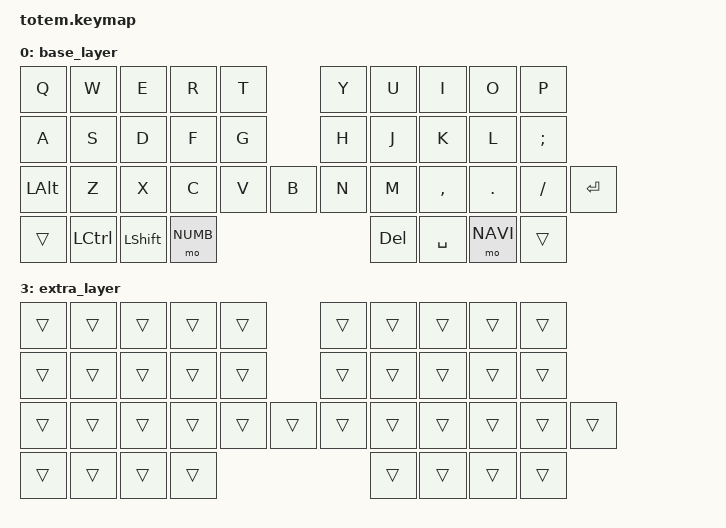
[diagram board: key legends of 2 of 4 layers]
#include <behaviors.dtsi>
#include <dt-bindings/zmk/keys.h>
#include <dt-bindings/zmk/bt.h>
#include <dt-bindings/zmk/outputs.h>

/* Helper: 이 레포의 ZMK_LAYER / 키 포지션 매크로를 사용 */
#include "./totem_key_position.h"
#include "./totem_macro.h"

/* ===================== */
/* Layer index (스샷 기준) */
/* ===================== */
#define BASE  0
#define NUMB  1   /* mo(1) */
#define NAVI  2   /* mo(2) */
#define EXTRA 3   /* 스샷의 mo(3) 자리 때문에 비워둠 */

/* Alias */
#define __________ &trans

/* ===================== */
/* Keymap                */
/* ===================== */

/*
스샷 기준 물리 배치 해석:
- 3번째 줄(하단 row)에 좌/우 "추가 1키"가 있음:
  - 왼쪽 추가키 = ALT
  - 오른쪽 추가키 = Enter
- 엄지 row(각 3키):
  - 왼쪽: ctrl / shift / mo(1)=NUMB
  - 오른쪽: del / space / mo(2)=NAVI
*/

/* --------------------- */
/* BASE                  */
/* --------------------- */
ZMK_LAYER(base_layer, /*
╭────────────┬────────────┬────────────┬────────────┬────────────╮╭────────────┬────────────┬────────────┬────────────┬────────────╮
*/&kp Q        &kp W        &kp E        &kp R        &kp T         &kp Y        &kp U        &kp I        &kp O        &kp P     /*
├────────────┼────────────┼────────────┼────────────┼────────────┤├────────────┼────────────┼────────────┼────────────┼────────────┤
*/&kp A        &kp S        &kp D        &kp F        &kp G         &kp H        &kp J        &kp K        &kp L        &kp SEMI  /*
├────────────┼────────────┼────────────┼────────────┼────────────┤├────────────┼────────────┼────────────┼────────────┼────────────┤
*/&kp LALT     &kp Z        &kp X        &kp C        &kp V  &kp B   &kp N        &kp M        &kp COMMA    &kp DOT      &kp FSLH   &kp ENTER/*
╰────────────┴────────────┴────────────┴────────────┴────────────╯╰────────────┴────────────┴────────────┴────────────┴────────────╯
╭────────────╮            ╭────────────┬────────────┬────────────╮╭────────────┬────────────┬────────────╮            ╭────────────╮
*/__________                &kp LCTRL     &kp LSHIFT   &mo NUMB      &kp DEL      &kp SPACE    &mo NAVI                __________/*
╰────────────╯            ╰────────────┴────────────┴────────────╯╰────────────┴────────────┴────────────╯            ╰────────────╯
*/)

/* --------------------- */
/* NUMB (mo(1))          */
/* --------------------- */
ZMK_LAYER(numb_layer, /*
╭────────────┬────────────┬────────────┬────────────┬────────────╮╭────────────┬────────────┬────────────┬────────────┬────────────╮
*/&kp N1       &kp N2       &kp N3       &kp N4       &kp N5        &kp N6       &kp N7       &kp N8       &kp N9       &kp N0     /*
├────────────┼────────────┼────────────┼────────────┼────────────┤├────────────┼────────────┼────────────┼────────────┼────────────┤
*/&kp EXCL     &kp AT       &kp HASH     &kp DLLR     &kp PRCNT     &kp CARET    &kp AMPS     &kp STAR     &kp LPAR     &kp RPAR   /*
├────────────┼────────────┼────────────┼────────────┼────────────┤├────────────┼────────────┼────────────┼────────────┼────────────┤
*/&kp ESC      &kp LC(A)    &kp LC(X)    &kp LC(C)    &kp LC(V) &kp LC(ENTER)   &kp MINUS    &kp LBKT     &kp RBKT     __________   &kp LA(TAB)/*
╰────────────┴────────────┴────────────┴────────────┴────────────╯╰────────────┴────────────┴────────────┴────────────┴────────────╯
╭────────────╮            ╭────────────┬────────────┬────────────╮╭────────────┬────────────┬────────────╮            ╭────────────╮
*/__________                &kp LANG1     &mo NAVI     &trans      &kp EQUAL    &kp LSHIFT   &mo EXTRA               __________/*
╰────────────╯            ╰────────────┴────────────┴────────────╯╰────────────┴────────────┴────────────╯            ╰────────────╯
*/)

/*
- 스샷의 -/_ 는 MINUS(Shift 시 _)
- 스샷의 +/= 는 EQUAL(Shift 시 +)
- 스샷의 [/{ 와 ]/} 는 LBKT/RBKT(Shift 시 { })
- alt+tab은 LA(TAB)
- LCTRL+ENTER는 LC(ENTER)
- mo(3)은 EXTRA 레이어로 두되, 아직 비워둠
*/

/* --------------------- */
/* NAVI (mo(2))          */
/* --------------------- */
ZMK_LAYER(navi_layer, /*
╭────────────┬────────────┬────────────┬────────────┬────────────╮╭────────────┬────────────┬────────────┬────────────┬────────────╮
*/&kp F1       &kp F2       &kp F3       &kp F4       &kp F5        &kp F6       &kp F7       &kp F8       &kp F9       &kp F10    /*
├────────────┼────────────┼────────────┼────────────┼────────────┤├────────────┼────────────┼────────────┼────────────┼────────────┤
*/&kp HOME     __________    __________    &kp F11      &kp F12       __________   &kp UP       __________   &kp PG_UP    &kp C_VOL_UP/*
├────────────┼────────────┼────────────┼────────────┼────────────┤├────────────┼────────────┼────────────┼────────────┼────────────┤
*/&kp END      __________    __________    __________    __________    &kp LEFT     &kp DOWN     &kp RIGHT    &kp PG_DN    &kp C_VOL_DN &kp LA(TAB)/*
╰────────────┴────────────┴────────────┴────────────┴────────────╯╰────────────┴────────────┴────────────┴────────────┴────────────╯
╭────────────╮            ╭────────────┬────────────┬────────────╮╭────────────┬────────────┬────────────╮            ╭────────────╮
*/__________                __________    __________    __________    __________   __________    __________              __________/*
╰────────────╯            ╰────────────┴────────────┴────────────╯╰────────────┴────────────┴────────────╯            ╰────────────╯
*/)

/* --------------------- */
/* EXTRA (mo(3))         */
/* - 아직 미지정: 전부 투과 */
/* --------------------- */
ZMK_LAYER(extra_layer, /*
╭────────────┬────────────┬────────────┬────────────┬────────────╮╭────────────┬────────────┬────────────┬────────────┬────────────╮
*/__________   __________   __________   __________   __________    __________   __________   __________   __________   __________/*
├────────────┼────────────┼────────────┼────────────┼────────────┤├────────────┼────────────┼────────────┼────────────┼────────────┤
*/__________   __________   __________   __________   __________    __________   __________   __________   __________   __________/*
├────────────┼────────────┼────────────┼────────────┼────────────┤├────────────┼────────────┼────────────┼────────────┼────────────┤
*/__________   __________   __________   __________   __________   __________    __________   __________   __________   __________   __________   __________/*
╰────────────┴────────────┴────────────┴────────────┴────────────╯╰────────────┴────────────┴────────────┴────────────┴────────────╯
╭────────────╮            ╭────────────┬────────────┬────────────╮╭────────────┬────────────┬────────────╮            ╭────────────╮
*/__________                __________   __________   __________    __________   __________   __________               __________/*
╰────────────╯            ╰────────────┴────────────┴────────────╯╰────────────┴────────────┴────────────╯            ╰────────────╯
*/)
